# ioat91sam3s1 register map
Registers are 32-bit, access not given, no defined reset value unless marked. A register's access mark holds for its fields unless they carry their own. Addresses are absolute; registers are grouped by the start of their names; [hi:lo] are bit positions; {n}, {i} and the like mark numbered series; 'fields as' and 'values as' point back to an identical list.

## TWI0
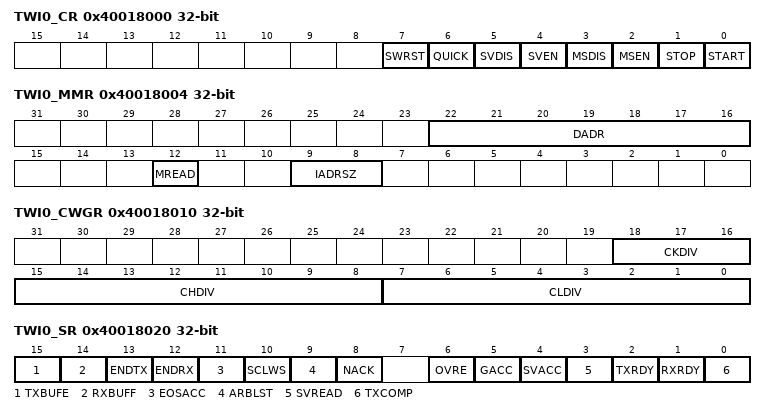
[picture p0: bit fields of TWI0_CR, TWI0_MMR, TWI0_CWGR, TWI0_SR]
0x40018000 TWI0_CR
  [7] SWRST, [6] QUICK, [5] SVDIS, [4] SVEN, [3] MSDIS, [2] MSEN, [1] STOP, [0] START
0x40018004 TWI0_MMR
  [22:16] DADR, [12] MREAD, [9:8] IADRSZ
0x40018008 TWI0_SMR
  [22:16] SADR
0x4001800C TWI0_IADR
  [23:0] IADR
0x40018010 TWI0_CWGR
  [18:16] CKDIV, [15:8] CHDIV, [7:0] CLDIV
0x40018020 TWI0_SR
  [15] TXBUFE, [14] RXBUFF, [13] ENDTX, [12] ENDRX, [11] EOSACC, [10] SCLWS, [9] ARBLST, [8] NACK, [6] OVRE, [5] GACC, [4] SVACC, [3] SVREAD, [2] TXRDY, [1] RXRDY, [0] TXCOMP
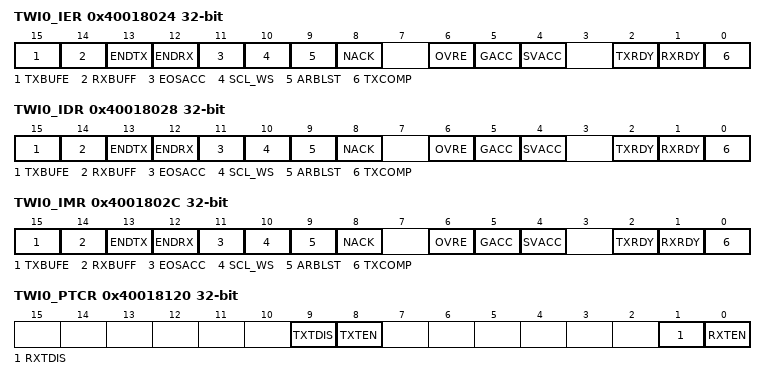
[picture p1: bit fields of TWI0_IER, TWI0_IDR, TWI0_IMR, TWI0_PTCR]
0x40018024 TWI0_IER
  [15] TXBUFE, [14] RXBUFF, [13] ENDTX, [12] ENDRX, [11] EOSACC, [10] SCL_WS, [9] ARBLST, [8] NACK, [6] OVRE, [5] GACC, [4] SVACC, [2] TXRDY, [1] RXRDY, [0] TXCOMP
0x40018028 TWI0_IDR
  fields as TWI0_IER
0x4001802C TWI0_IMR
  fields as TWI0_IER
0x40018030 TWI0_RHR
  [7:0] RXDATA
0x40018034 TWI0_THR
  [7:0] TXDATA
0x40018100 TWI0_RPR
  [31:0] RXPTR
0x40018104 TWI0_RCR
  [15:0] RXCTR
0x40018108 TWI0_TPR
  [31:0] TXPTR
0x4001810C TWI0_TCR
  [15:0] TXCTR
0x40018110 TWI0_RNPR
  [31:0] RXNPTR
0x40018114 TWI0_RNCR
  [15:0] RXNCTR
0x40018118 TWI0_TNPR
  [31:0] TXNPTR
0x4001811C TWI0_TNCR
  [15:0] TXNCTR
0x40018120 TWI0_PTCR
  [9] TXTDIS, [8] TXTEN, [1] RXTDIS, [0] RXTEN
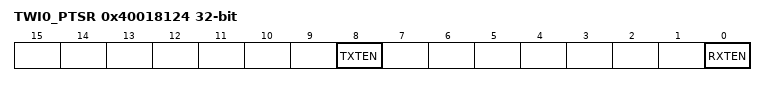
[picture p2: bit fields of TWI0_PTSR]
0x40018124 TWI0_PTSR
  [8] TXTEN, [0] RXTEN

## TWI1
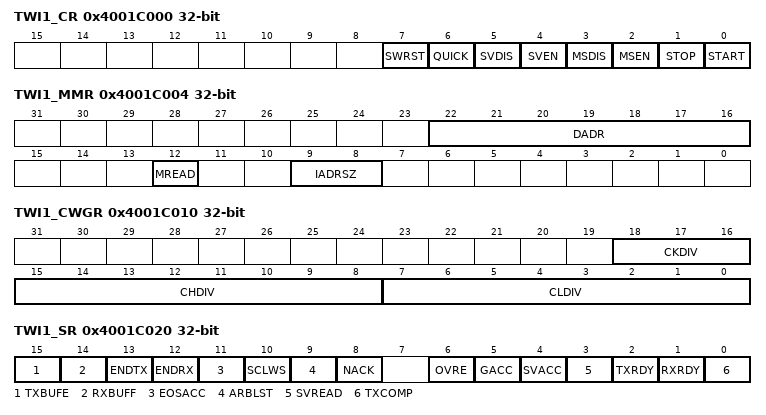
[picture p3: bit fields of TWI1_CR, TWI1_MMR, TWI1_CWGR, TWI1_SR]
0x4001C000 TWI1_CR
  [7] SWRST, [6] QUICK, [5] SVDIS, [4] SVEN, [3] MSDIS, [2] MSEN, [1] STOP, [0] START
0x4001C004 TWI1_MMR
  [22:16] DADR, [12] MREAD, [9:8] IADRSZ
0x4001C008 TWI1_SMR
  [22:16] SADR
0x4001C00C TWI1_IADR
  [23:0] IADR
0x4001C010 TWI1_CWGR
  [18:16] CKDIV, [15:8] CHDIV, [7:0] CLDIV
0x4001C020 TWI1_SR
  [15] TXBUFE, [14] RXBUFF, [13] ENDTX, [12] ENDRX, [11] EOSACC, [10] SCLWS, [9] ARBLST, [8] NACK, [6] OVRE, [5] GACC, [4] SVACC, [3] SVREAD, [2] TXRDY, [1] RXRDY, [0] TXCOMP
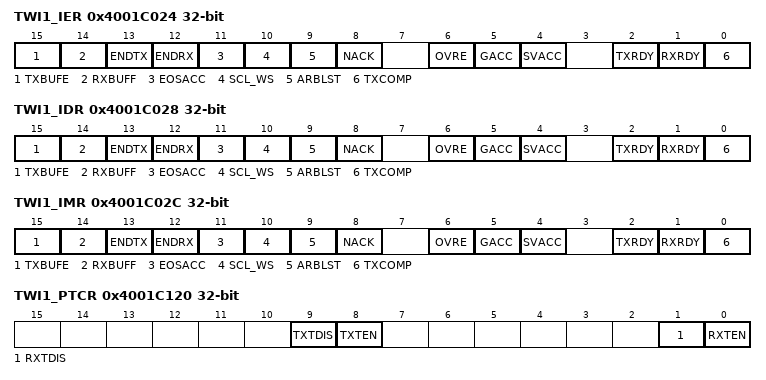
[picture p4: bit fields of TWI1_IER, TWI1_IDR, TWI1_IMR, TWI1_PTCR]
0x4001C024 TWI1_IER
  [15] TXBUFE, [14] RXBUFF, [13] ENDTX, [12] ENDRX, [11] EOSACC, [10] SCL_WS, [9] ARBLST, [8] NACK, [6] OVRE, [5] GACC, [4] SVACC, [2] TXRDY, [1] RXRDY, [0] TXCOMP
0x4001C028 TWI1_IDR
  fields as TWI1_IER
0x4001C02C TWI1_IMR
  fields as TWI1_IER
0x4001C030 TWI1_RHR
  [7:0] RXDATA
0x4001C034 TWI1_THR
  [7:0] TXDATA
0x4001C100 TWI1_RPR
  [31:0] RXPTR
0x4001C104 TWI1_RCR
  [15:0] RXCTR
0x4001C108 TWI1_TPR
  [31:0] TXPTR
0x4001C10C TWI1_TCR
  [15:0] TXCTR
0x4001C110 TWI1_RNPR
  [31:0] RXNPTR
0x4001C114 TWI1_RNCR
  [15:0] RXNCTR
0x4001C118 TWI1_TNPR
  [31:0] TXNPTR
0x4001C11C TWI1_TNCR
  [15:0] TXNCTR
0x4001C120 TWI1_PTCR
  [9] TXTDIS, [8] TXTEN, [1] RXTDIS, [0] RXTEN
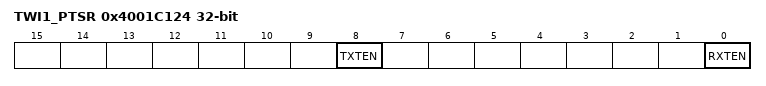
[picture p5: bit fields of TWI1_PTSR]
0x4001C124 TWI1_PTSR
  [8] TXTEN, [0] RXTEN

## PWM
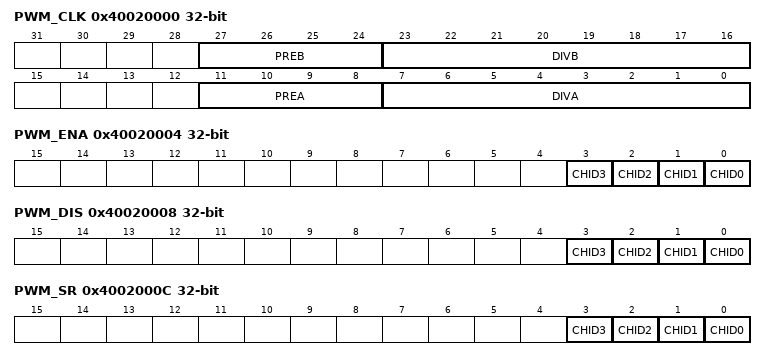
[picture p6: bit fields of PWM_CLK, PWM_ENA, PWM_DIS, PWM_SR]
0x40020000 PWM_CLK
  [27:24] PREB, [23:16] DIVB, [11:8] PREA, [7:0] DIVA
0x40020004 PWM_ENA
  [n] CHID{n} (n=0..3)
0x40020008 PWM_DIS
  [n] CHID{n} (n=0..3)
0x4002000C PWM_SR
  [n] CHID{n} (n=0..3)
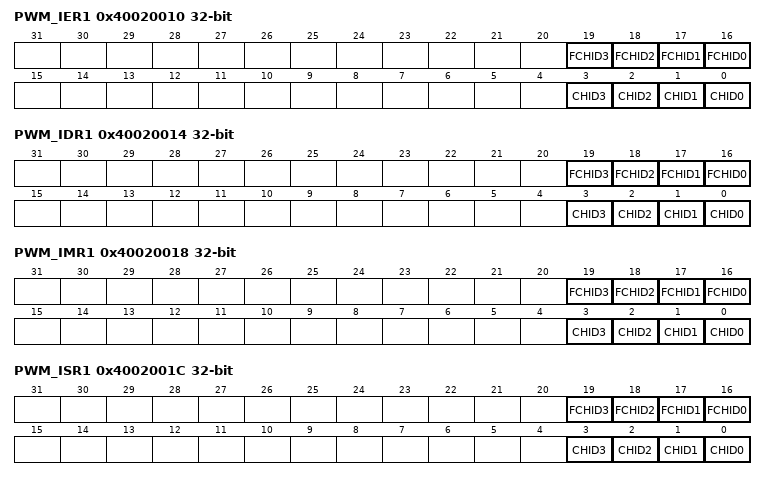
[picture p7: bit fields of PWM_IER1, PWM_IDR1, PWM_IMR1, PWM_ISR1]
0x40020010 PWM_IER1
  [n+16] FCHID{n} (n=0..3), [n] CHID{n} (n=0..3)
0x40020014 PWM_IDR1
  [n+16] FCHID{n} (n=0..3), [n] CHID{n} (n=0..3)
0x40020018 PWM_IMR1
  [n+16] FCHID{n} (n=0..3), [n] CHID{n} (n=0..3)
0x4002001C PWM_ISR1
  [n+16] FCHID{n} (n=0..3), [n] CHID{n} (n=0..3)
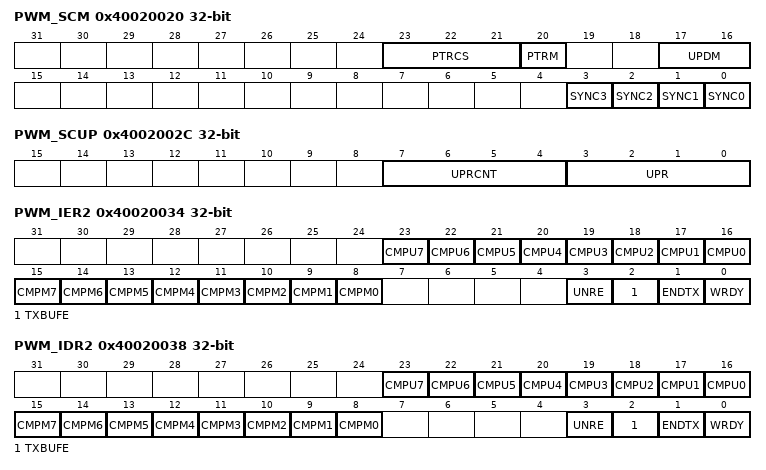
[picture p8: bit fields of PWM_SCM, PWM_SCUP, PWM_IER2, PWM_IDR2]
0x40020020 PWM_SCM
  [23:21] PTRCS, [20] PTRM, [17:16] UPDM, [n] SYNC{n} (n=0..3)
0x40020028 PWM_SCUC
  [0] UPDULOCK
0x4002002C PWM_SCUP
  [7:4] UPRCNT, [3:0] UPR
0x40020030 PWM_SCUPUPD
  [3:0] UPRUPD
0x40020034 PWM_IER2
  [n+16] CMPU{n} (n=0..7), [n+8] CMPM{n} (n=0..7), [3] UNRE, [2] TXBUFE, [1] ENDTX, [0] WRDY
0x40020038 PWM_IDR2
  fields as PWM_IER2
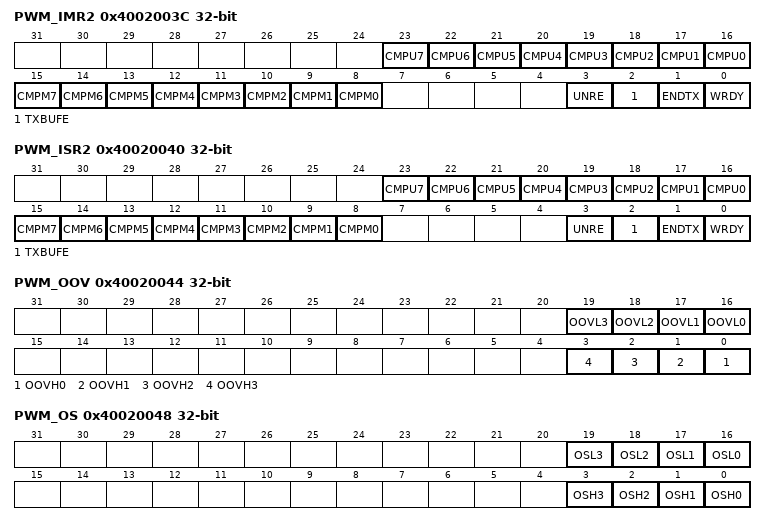
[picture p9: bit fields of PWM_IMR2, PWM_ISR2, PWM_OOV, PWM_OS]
0x4002003C PWM_IMR2
  fields as PWM_IER2
0x40020040 PWM_ISR2
  fields as PWM_IER2
0x40020044 PWM_OOV
  [n+16] OOVL{n} (n=0..3), [n] OOVH{n} (n=0..3)
0x40020048 PWM_OS
  [n+16] OSL{n} (n=0..3), [n] OSH{n} (n=0..3)
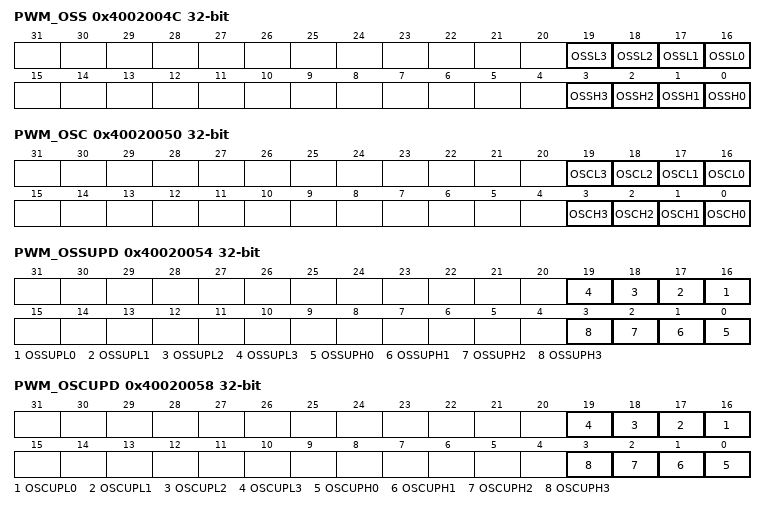
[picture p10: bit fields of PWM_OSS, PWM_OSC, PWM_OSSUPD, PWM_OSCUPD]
0x4002004C PWM_OSS
  [n+16] OSSL{n} (n=0..3), [n] OSSH{n} (n=0..3)
0x40020050 PWM_OSC
  [n+16] OSCL{n} (n=0..3), [n] OSCH{n} (n=0..3)
0x40020054 PWM_OSSUPD
  [n+16] OSSUPL{n} (n=0..3), [n] OSSUPH{n} (n=0..3)
0x40020058 PWM_OSCUPD
  [n+16] OSCUPL{n} (n=0..3), [n] OSCUPH{n} (n=0..3)
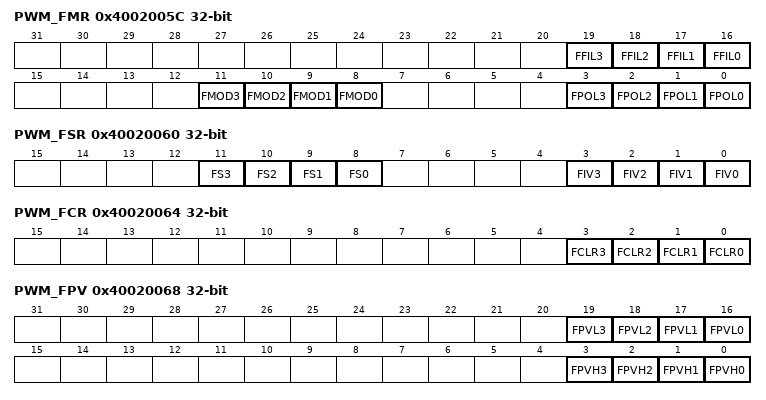
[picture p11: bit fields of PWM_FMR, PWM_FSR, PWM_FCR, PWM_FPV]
0x4002005C PWM_FMR
  [n+16] FFIL{n} (n=0..3), [n+8] FMOD{n} (n=0..3), [n] FPOL{n} (n=0..3)
0x40020060 PWM_FSR
  [n+8] FS{n} (n=0..3), [n] FIV{n} (n=0..3)
0x40020064 PWM_FCR
  [n] FCLR{n} (n=0..3)
0x40020068 PWM_FPV
  [n+16] FPVL{n} (n=0..3), [n] FPVH{n} (n=0..3)
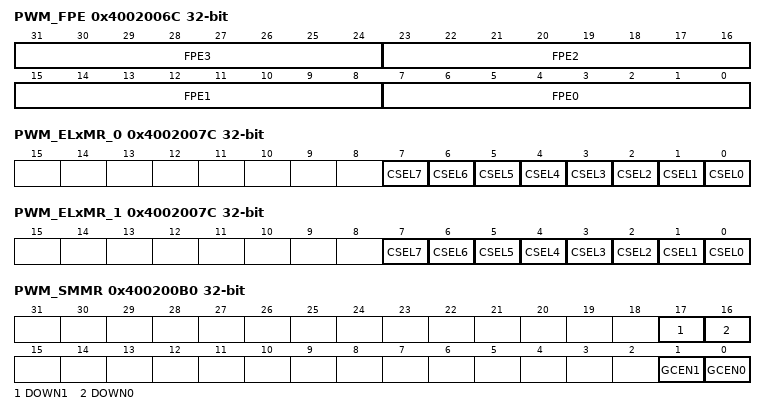
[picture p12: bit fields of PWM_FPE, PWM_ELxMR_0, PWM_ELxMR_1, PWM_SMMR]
0x4002006C PWM_FPE
  [8n+7:8n] FPE{n} (n=0..3)
0x4002007C PWM_ELxMR_0
  [n] CSEL{n} (n=0..7)
0x4002007C PWM_ELxMR_1
  [n] CSEL{n} (n=0..7)
0x400200B0 PWM_SMMR
  [17] DOWN1, [16] DOWN0, [1] GCEN1, [0] GCEN0
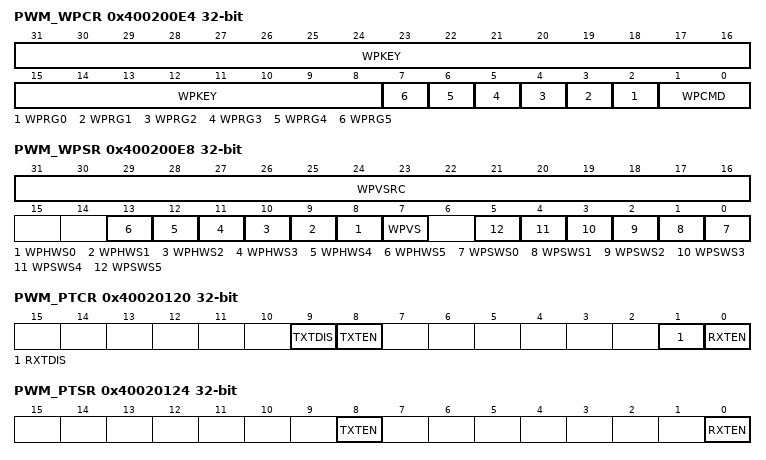
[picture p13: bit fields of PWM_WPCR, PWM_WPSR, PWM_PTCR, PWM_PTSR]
0x400200E4 PWM_WPCR
  [31:8] WPKEY, [n+2] WPRG{n} (n=0..5), [1:0] WPCMD
0x400200E8 PWM_WPSR
  [31:16] WPVSRC, [n+8] WPHWS{n} (n=0..5), [7] WPVS, [n] WPSWS{n} (n=0..5)
0x40020100 PWM_RPR
  [31:0] RXPTR
0x40020104 PWM_RCR
  [15:0] RXCTR
0x40020108 PWM_TPR
  [31:0] TXPTR
0x4002010C PWM_TCR
  [15:0] TXCTR
0x40020110 PWM_RNPR
  [31:0] RXNPTR
0x40020114 PWM_RNCR
  [15:0] RXNCTR
0x40020118 PWM_TNPR
  [31:0] TXNPTR
0x4002011C PWM_TNCR
  [15:0] TXNCTR
0x40020120 PWM_PTCR
  [9] TXTDIS, [8] TXTEN, [1] RXTDIS, [0] RXTEN
0x40020124 PWM_PTSR
  [8] TXTEN, [0] RXTEN
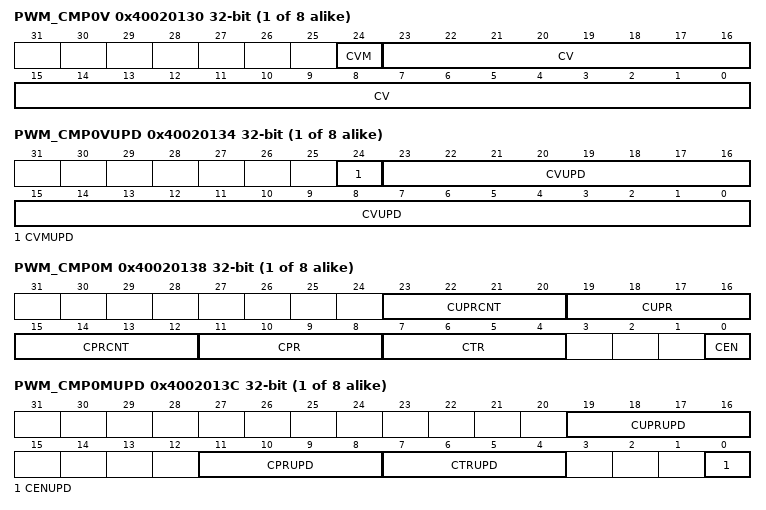
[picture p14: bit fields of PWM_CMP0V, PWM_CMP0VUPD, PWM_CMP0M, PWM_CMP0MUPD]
{0x40020130+0x10*i} PWM_CMP{i}V (i=0..7)
  [24] CVM, [23:0] CV
{0x40020134+0x10*i} PWM_CMP{i}VUPD (i=0..7)
  [24] CVMUPD, [23:0] CVUPD
{0x40020138+0x10*i} PWM_CMP{i}M (i=0..7)
  [23:20] CUPRCNT, [19:16] CUPR, [15:12] CPRCNT, [11:8] CPR, [7:4] CTR, [0] CEN
{0x4002013C+0x10*i} PWM_CMP{i}MUPD (i=0..7)
  [19:16] CUPRUPD, [11:8] CPRUPD, [7:4] CTRUPD, [0] CENUPD
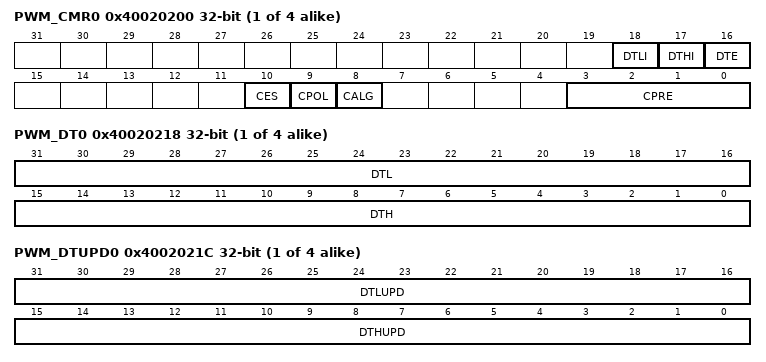
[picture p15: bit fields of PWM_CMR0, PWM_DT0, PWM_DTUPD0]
{0x40020200+0x20*i} PWM_CMR{i} (i=0..3)
  [18] DTLI, [17] DTHI, [16] DTE, [10] CES, [9] CPOL, [8] CALG, [3:0] CPRE
{0x40020204+0x20*i} PWM_CDTY{i} (i=0..3)
  [23:0] CDTY
{0x40020208+0x20*i} PWM_CDTYUPD{i} (i=0..3)
  [23:0] CDTYUPD
{0x4002020C+0x20*i} PWM_CPRD{i} (i=0..3)
  [23:0] CPRD
{0x40020210+0x20*i} PWM_CPRDUPD{i} (i=0..3)
  [23:0] CPRDUPD
{0x40020214+0x20*i} PWM_CCNT{i} (i=0..3)
  [23:0] CNT
{0x40020218+0x20*i} PWM_DT{i} (i=0..3)
  [31:16] DTL, [15:0] DTH
{0x4002021C+0x20*i} PWM_DTUPD{i} (i=0..3)
  [31:16] DTLUPD, [15:0] DTHUPD

## Notices in the file
Copyright (c) 2009, Atmel Corporation
All rights reserved.
Redistribution and use in source and binary forms, with or without
modification, are permitted provided that the following condition is met:
- Redistributions of source code must retain the above copyright notice,
this list of conditions and the disclaimer below.
Atmel's name may not be used to endorse or promote products derived from
this software without specific prior written permission.
DISCLAIMER:  THIS SOFTWARE IS PROVIDED BY ATMEL "AS IS" AND ANY EXPRESS OR
IMPLIED WARRANTIES, INCLUDING, BUT NOT LIMITED TO, THE IMPLIED WARRANTIES OF
MERCHANTABILITY, FITNESS FOR A PARTICULAR PURPOSE AND NON-INFRINGEMENT ARE
DISCLAIMED. IN NO EVENT SHALL ATMEL BE LIABLE FOR ANY DIRECT, INDIRECT,
INCIDENTAL, SPECIAL, EXEMPLARY, OR CONSEQUENTIAL DAMAGES (INCLUDING, BUT NOT
LIMITED TO, PROCUREMENT OF SUBSTITUTE GOODS OR SERVICES; LOSS OF USE, DATA,
OR PROFITS; OR BUSINESS INTERRUPTION) HOWEVER CAUSED AND ON ANY THEORY OF
LIABILITY, WHETHER IN CONTRACT, STRICT LIABILITY, OR TORT (INCLUDING
NEGLIGENCE OR OTHERWISE) ARISING IN ANY WAY OUT OF THE USE OF THIS SOFTWARE,
EVEN IF ADVISED OF THE POSSIBILITY OF SUCH DAMAGE.
